# ATmega16U2 device description
Architecture: AVR8; Family: megaAVR
Registers are 8-bit, access not given, no defined reset value unless marked. A register's access mark holds for its fields unless they carry their own. Offsets are from the block's base; [hi:lo] are bit positions.

## LOCKBIT — Lockbits
Instances: LOCKBIT 0 in lockbits
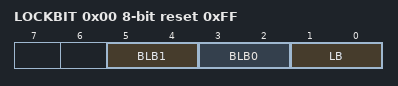
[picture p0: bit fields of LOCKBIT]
0x00 LOCKBIT reset 0xFF
  [5:4] BLB1 — Boot Loader Protection Mode
    0=LPM_SPM_DISABLE (LPM and SPM prohibited in Boot Section); 1=LPM_DISABLE (LPM prohibited in Boot Section); 2=SPM_DISABLE (SPM prohibited in Boot Section); 3=NO_LOCK (No lock on SPM and LPM in Boot Section)
  [3:2] BLB0 — Boot Loader Protection Mode
    0=LPM_SPM_DISABLE (LPM and SPM prohibited in Application Section); 1=LPM_DISABLE (LPM prohibited in Application Section); 2=SPM_DISABLE (SPM prohibited in Application Section); 3=NO_LOCK (No lock on SPM and LPM in Application Section)
  [1:0] LB — Memory Lock
    0=PROG_VER_DISABLED (Further programming and verification disabled); 2=PROG_DISABLED (Further programming disabled); 3=NO_LOCK (No memory lock features enabled)

## PORTB — I/O Port
Instances: PORTB 0x00
0x23 PINB — Port B Input Pins
0x24 DDRB — Port B Data Direction Register
0x25 PORTB — Port B Data Register

## PORTD — I/O Port
Instances: PORTD 0x00
0x29 PIND — Port D Input Pins
0x2A DDRD — Port D Data Direction Register
0x2B PORTD — Port D Data Register

## PORTC — I/O Port
Instances: PORTC 0x00
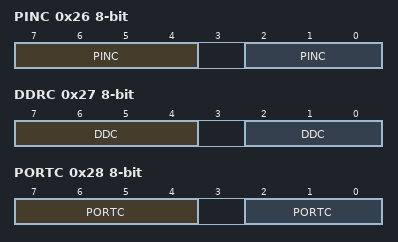
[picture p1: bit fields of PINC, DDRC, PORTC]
0x26 PINC — Port C Input Pins
  [7:4] PINC (bit 4 of the value upward) — Port C Input Pins bits
  [2:0] PINC — Port C Input Pins bits
0x27 DDRC — Port C Data Direction Register
  [7:4] DDC (bit 4 of the value upward) — Port C Data Direction Register bits
  [2:0] DDC — Port C Data Direction Register bits
0x28 PORTC — Port C Data Register
  [7:4] PORTC (bit 4 of the value upward) — Port C Data Register bits
  [2:0] PORTC — Port C Data Register bits

## SPI — Serial Peripheral Interface
Instances: SPI 0x00
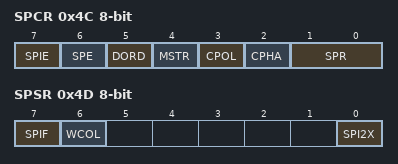
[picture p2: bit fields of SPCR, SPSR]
0x4C SPCR — SPI Control Register
  [7] SPIE — SPI Interrupt Enable
  [6] SPE — SPI Enable
  [5] DORD — Data Order
  [4] MSTR — Master/Slave Select
  [3] CPOL — Clock polarity
  [2] CPHA — Clock Phase
  [1:0] SPR — SPI Clock Rate Selects
    0=fosc/4; 1=fosc/16; 2=fosc/64; 3=fosc/128; 4=fosc/2; 5=fosc/8; 6=fosc/32; 7=fosc/64
0x4D SPSR — SPI Status Register
  [7] SPIF — SPI Interrupt Flag
  [6] WCOL — Write Collision Flag
  [0] SPI2X — Double SPI Speed Bit
0x4E SPDR — SPI Data Register
  [7:0] SPDR — SPI Data bits

## BOOT_LOAD — Bootloader
Instances: BOOT_LOAD 0x00
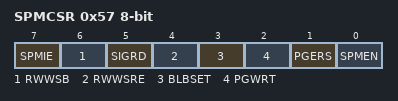
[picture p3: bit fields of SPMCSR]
0x57 SPMCSR — Store Program Memory Control Register
  [7] SPMIE — SPM Interrupt Enable
  [6] RWWSB — Read While Write Section Busy
  [5] SIGRD — Signature Row Read
  [4] RWWSRE — Read While Write section read enable
  [3] BLBSET — Boot Lock Bit Set
  [2] PGWRT — Page Write
  [1] PGERS — Page Erase
  [0] SPMEN — Store Program Memory Enable

## EEPROM
Instances: EEPROM 0x00
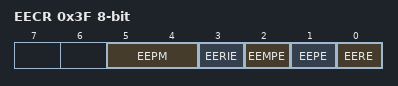
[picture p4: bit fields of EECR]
0x3F EECR — EEPROM Control Register
  [5:4] EEPM — EEPROM Programming Mode Bits
    0=Erase and Write in one operation; 1=Erase Only; 2=Write Only
  [3] EERIE — EEPROM Ready Interrupt Enable
  [2] EEMPE — EEPROM Master Write Enable
  [1] EEPE — EEPROM Write Enable
  [0] EERE — EEPROM Read Enable
0x40 EEDR — EEPROM Data Register
  [7:0] EEDR — EEPROM Data bits
0x41 EEAR 16-bit — EEPROM Address Register Low Bytes
  [11:0] EEAR — EEPROM Address bits

## TC0 (TC8 module) — Timer/Counter, 8-bit
Instances: TC0 0x00
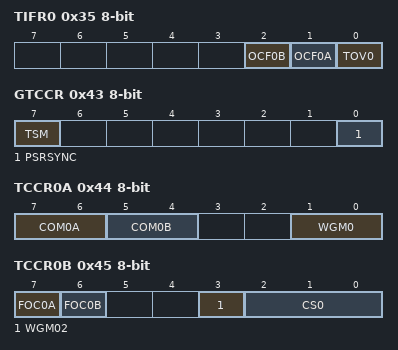
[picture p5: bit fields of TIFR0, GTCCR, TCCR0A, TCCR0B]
0x35 TIFR0 — Timer/Counter0 Interrupt Flag register
  [2] OCF0B — Timer/Counter0 Output Compare Flag 0B
  [1] OCF0A — Timer/Counter0 Output Compare Flag 0A
  [0] TOV0 — Timer/Counter0 Overflow Flag
0x43 GTCCR — General Timer/Counter Control Register
  [7] TSM — Timer/Counter Synchronization Mode
  [0] PSRSYNC — Prescaler Reset Timer/Counter1 and Timer/Counter0
0x44 TCCR0A — Timer/Counter Control Register A
  [7:6] COM0A — Compare Output Mode, Phase Correct PWM Mode
  [5:4] COM0B — Compare Output Mode, Fast PWm
  [1:0] WGM0 — Waveform Generation Mode
0x45 TCCR0B — Timer/Counter Control Register B
  [7] FOC0A — Force Output Compare A
  [6] FOC0B — Force Output Compare B
  [3] WGM02
  [2:0] CS0 — Clock Select
    0=No Clock Source (Stopped); 1=Running, No Prescaling; 2=Running, CLK/8; 3=Running, CLK/64; 4=Running, CLK/256; 5=Running, CLK/1024; 6=Running, ExtClk Tx Falling Edge; 7=Running, ExtClk Tx Rising Edge
0x46 TCNT0 — Timer/Counter0
  [7:0] TCNT0 — Timer/Counter0 bits
0x47 OCR0A — Timer/Counter0 Output Compare Register
  [7:0] OCR0A — Timer/Counter0 Output Compare A bits
0x48 OCR0B — Timer/Counter0 Output Compare Register
  [7:0] OCR0B — Timer/Counter0 Output Compare B bits
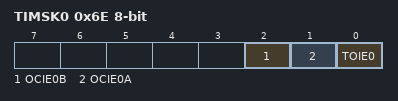
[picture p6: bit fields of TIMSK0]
0x6E TIMSK0 — Timer/Counter0 Interrupt Mask Register
  [2] OCIE0B — Timer/Counter0 Output Compare Match B Interrupt Enable
  [1] OCIE0A — Timer/Counter0 Output Compare Match A Interrupt Enable
  [0] TOIE0 — Timer/Counter0 Overflow Interrupt Enable
